# 3061HRPIKZ register map
File version: 1.0
Registers are 32-bit, access per field, reset 0x0 unless marked. A register's access mark holds for its fields unless they carry their own. Offsets are from the block's base; [hi:lo] are bit positions; {n}, {i} and the like mark numbered series.

## CAPM_COMM — capm_comm peripheral interface
Base 0x14B03000
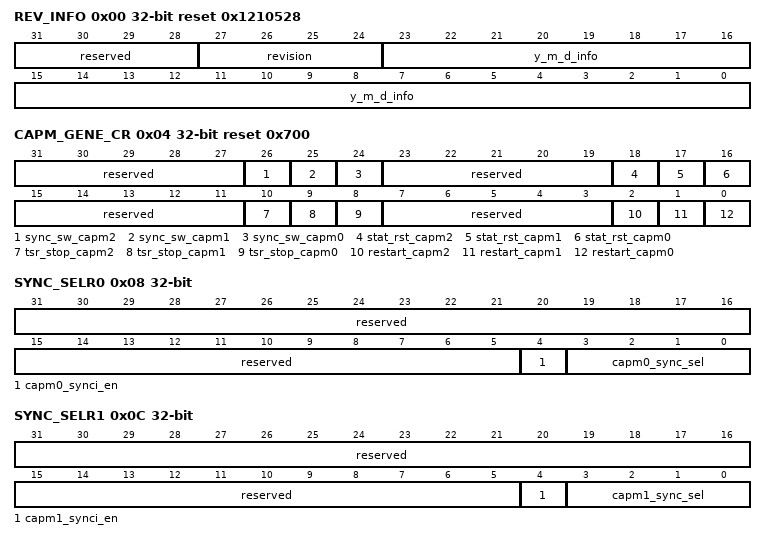
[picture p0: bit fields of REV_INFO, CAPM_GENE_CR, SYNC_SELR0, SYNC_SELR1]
0x00 REV_INFO ro reset 0x1210528 — Revision Information，版本信息寄存器。
  [31:28] reserved — 保留。
  [27:24] revision — IP版本号。
  [23:0] y_m_d_info — 版本日期（20XX年/月/日）。
0x04 CAPM_GENE_CR reset 0x700 — Capture module general control Reg，通用配置寄存器。包含：软件同步触发、工作状态复位和 TSR 计数器启停控制。
  [31:27] reserved ro — 保留。
  [26] sync_sw_capm2 rw write-1-clears — 触发CAPM2同步，对TSR置位，复位捕获序列。软件写1后自动清零。 0：不同步； 1：同步。写1后自动清零。
  [25] sync_sw_capm1 rw write-1-clears — 触发CAPM1同步，对TSR置位，复位捕获序列。软件写1后自动清零。 0：不同步； 1：同步。写1后自动清零。
  [24] sync_sw_capm0 rw write-1-clears — 触发CAPM0同步，对TSR置位，复位捕获序列。软件写1后自动清零。 0：不同步； 1：同步。写1后自动清零。
  [23:19] reserved ro — 保留。
  [18] stat_rst_capm2 rw write-1-clears — CAPM2工作状态复位，复位范围包括：TSR计数器、EAR计数器、捕获序列、TSR分频计数器和原始中断。 0：不复位； 1：复位。写1后自动清零。
  [17] stat_rst_capm1 rw write-1-clears — CAPM1工作状态复位，复位范围包括：TSR计数器、EAR计数器、捕获序列、TSR分频计数器和原始中断。 0：不复位； 1：复位。写1后自动清零。
  [16] stat_rst_capm0 rw write-1-clears — CAPM0工作状态复位，复位范围包括：TSR计数器、EAR计数器、捕获序列、TSR分频计数器和原始中断。 0：不复位； 1：复位。写1后自动清零。
  [15:11] reserved ro — 保留。
  [10] tsr_stop_capm2 rw — CAPM2 TSR暂停计数使能。 0：CAPM2 TSR继续计数； 1：CAPM2 TSR暂停计数。
  [9] tsr_stop_capm1 rw — CAPM1 TSR暂停计数使能。 0：CAPM2 TSR继续计数； 1：CAPM2 TSR暂停计数。
  [8] tsr_stop_capm0 rw — CAPM0 TSR暂停计数使能。 0：CAPM2 TSR继续计数； 1：CAPM2 TSR暂停计数。
  [7:3] reserved ro — 保留。
  [2] restart_capm2 rw write-1-clears — CAPM2开始一次新的单轮次捕获。 0：不开始； 1：开始。写1后自动清零。
  [1] restart_capm1 rw write-1-clears — CAPM1开始一次新的单轮次捕获。 0：不开始； 1：开始。写1后自动清零。
  [0] restart_capm0 rw write-1-clears — CAPM0开始一次新的单轮次捕获。 0：不开始； 1：开始。写1后自动清零。
0x08 SYNC_SELR0 — Sync Selection Register(for CAPM0)，CAPM0同步设置选择寄存器。
  [31:5] reserved ro — 保留。
  [4] capm0_synci_en rw — CAPM0 硬件，软件同步使能。 0：不使能； 1：使能。
  [3:0] capm0_sync_sel rw — CAPM0的硬件同步源选择。 0x0：无同步源； 0x1：APT0同步输出信号； 0x2：APT1同步输出信号； 0x3：APT2同步输出信号； 0x4：APT3同步输出信号； 0x5：APT4同步输出信号； 0x6：APT5同步输出信号； 0x7：APT6同步输出信号； 0x8：APT7同步输出信号； 0x9：APT8同步输出信号；0xA：无同步源； … 0xF：无同步源。
0x0C SYNC_SELR1 — Sync Selection Register(for CAPM1)，CAPM1同步设置选择寄存器。
  [31:5] reserved ro — 保留。
  [4] capm1_synci_en rw — CAPM1 硬件，软件同步使能。 0：不使能； 1：使能。
  [3:0] capm1_sync_sel rw — CAPM1的硬件同步源选择： 同capm0_sync_sel。
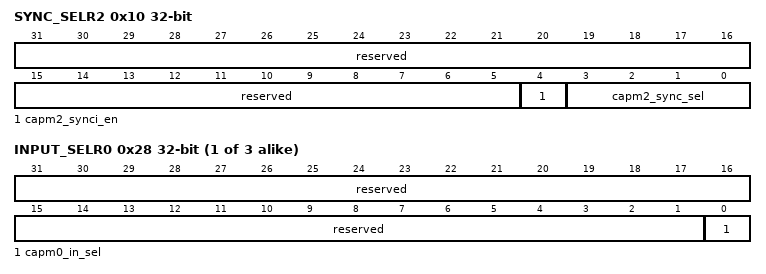
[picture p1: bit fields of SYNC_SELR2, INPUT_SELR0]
0x10 SYNC_SELR2 — Sync Selection Register(for CAPM2)，CAPM2同步设置选择寄存器。
  [31:5] reserved ro — 保留。
  [4] capm2_synci_en rw — CAPM2 硬件，软件同步使能。 0：不使能； 1：使能。
  [3:0] capm2_sync_sel rw — CAPM2的硬件同步源选择：同capm0_sync_sel。
{0x28+4i} INPUT_SELR{i} (i=0..2) — Input Source Selection Register(for CAPM{i})，CAPM{i}输入源选择寄存器。
  [31:1] reserved ro — 保留。
  [0] capm{i}_in_sel rw — CAPM{i}输入源选择。 0：CAPM{i}_SRC0； 1：CAPM{i}_SRC1。

## CFD — CFD_APB_REG peripheral interface
Base 0x10020000
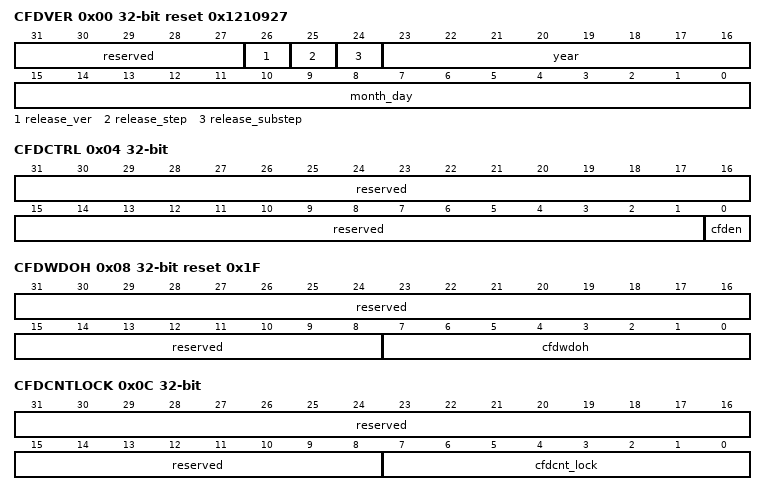
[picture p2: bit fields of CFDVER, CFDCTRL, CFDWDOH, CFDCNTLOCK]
0x00 CFDVER ro reset 0x1210927 — CFD Version，CFD版本信息寄存器。
  [31:27] reserved — 保留。
  [26] release_ver — 版本信息。
  [25] release_step — 版本信息。
  [24] release_substep — 版本信息。
  [23:16] year — 年。
  [15:0] month_day — 月日。
0x04 CFDCTRL — CFD Control，CFD控制寄存器。
  [31:1] reserved ro — 保留。
  [0] cfden rw — CFD 使能。 0：不使能； 1：使能。
0x08 CFDWDOH reset 0x1F — CFD Check Window High Value，CFD检查窗口上限寄存器。
  [31:8] reserved ro — 保留。
  [7:0] cfdwdoh rw — CFD 检查窗口上界限，默认为（从0x0计数到0x1F）32个LOSC周期即检测时间1ms，CFDCNT大于等于该值说明检测到PLL参考时钟失效（Clock_fail）。
0x0C CFDCNTLOCK ro — CFD Count Lock Value，CFD计数锁存值寄存器。
  [31:8] reserved — 保留。
  [7:0] cfdcnt_lock — CFD 内部计数器计数锁存值。
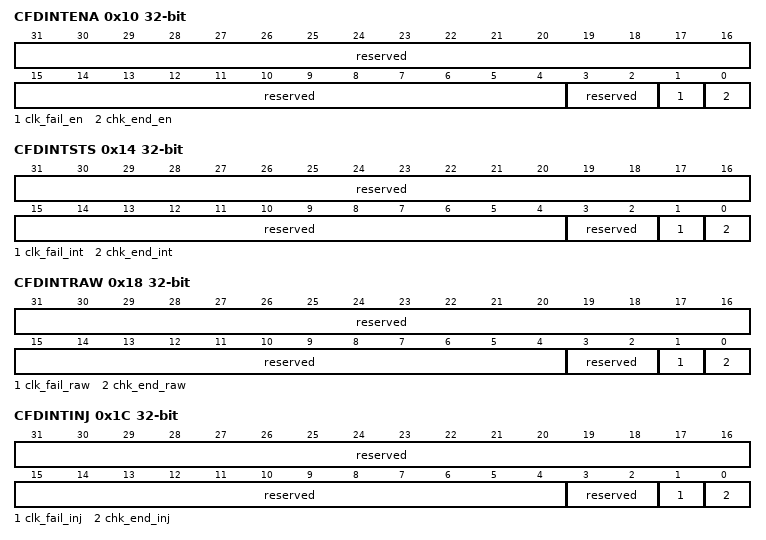
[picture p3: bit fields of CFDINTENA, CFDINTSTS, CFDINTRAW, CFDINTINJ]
0x10 CFDINTENA — CFD Interrupt Enable，CFD中断使能寄存器。
  [31:4] reserved ro — 保留。
  [3:2] reserved ro — 保留。
  [1] clk_fail_en rw — CFD 检测到PLL参考时钟失效中断使能。不使能时，即屏蔽相应的中断状态，不影响相应的原始中断。若全部不使能，CFD不会上报中断给CPU。 0：不使能； 1：使能。
  [0] chk_end_en rw — CFD 检测结束中断使能。 0：不使能； 1：使能。
0x14 CFDINTSTS ro — CFD Interrupt Status，CFD中断状态寄存器。
  [31:4] reserved — 保留。
  [3:2] reserved — 保留。
  [1] clk_fail_int — CFD 检测到PLL参考时钟失效中断。 0：无中断； 1：有中断。
  [0] chk_end_int — CFD 检测结束中断。 0：无中断； 1：有中断。
0x18 CFDINTRAW — CFD Raw Interrupt，CFD原始中断寄存器。
  [31:4] reserved ro — 保留。
  [3:2] reserved ro — 保留。
  [1] clk_fail_raw rw write-clears — CFD 检测到PLL参考时钟失效原始中断。当CMCTRL[cmen]为1时，才可能产生此中断。 0：无原始中断； 1：有原始中断。写1清除中断。
  [0] chk_end_raw rw write-clears — CFD 检测结束中断原始中断。当CMCTRL[cmen]为1时，才可能产生此中断。 0：无原始中断； 1：有原始中断。写1清除中断。
0x1C CFDINTINJ — CFD Interrupt Injection，CFD中断注入寄存器。
  [31:4] reserved ro — 保留。
  [3:2] reserved ro — 保留。
  [1] clk_fail_inj rw write-1-clears — CFD 检测到PLL参考时钟失效中断注入。 0：不注入； 1：注入。
  [0] chk_end_inj rw write-1-clears — CFD 检测结束中断注入。 0：不注入； 1：注入。
